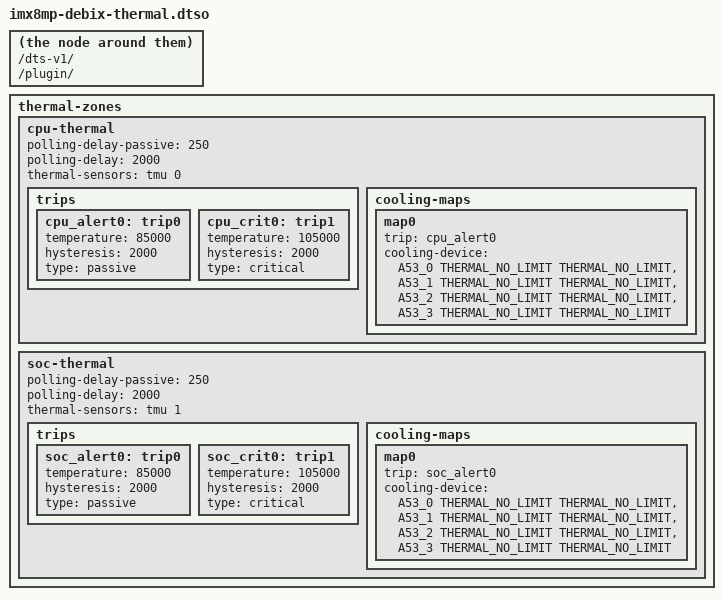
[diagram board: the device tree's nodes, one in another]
/dts-v1/;
/plugin/;

#include "imx8mp-pinfunc.h"
#include <dt-bindings/interrupt-controller/arm-gic.h>
#include <dt-bindings/thermal/thermal.h>

	thermal-zones {
		cpu-thermal {
			polling-delay-passive = <250>;
			polling-delay = <2000>;
			thermal-sensors = <&tmu 0>;
			trips {
				cpu_alert0: trip0 {
					temperature = <85000>;
					hysteresis = <2000>;
					type = "passive";
				};

				cpu_crit0: trip1 {
					temperature = <105000>;
					hysteresis = <2000>;
					type = "critical";
				};
			};

			cooling-maps {
				map0 {
					trip = <&cpu_alert0>;
					cooling-device =
						<&A53_0 THERMAL_NO_LIMIT THERMAL_NO_LIMIT>,
						<&A53_1 THERMAL_NO_LIMIT THERMAL_NO_LIMIT>,
						<&A53_2 THERMAL_NO_LIMIT THERMAL_NO_LIMIT>,
						<&A53_3 THERMAL_NO_LIMIT THERMAL_NO_LIMIT>;
				};
			};
		};

		soc-thermal {
			polling-delay-passive = <250>;
			polling-delay = <2000>;
			thermal-sensors = <&tmu 1>;
			trips {
				soc_alert0: trip0 {
					temperature = <85000>;
					hysteresis = <2000>;
					type = "passive";
				};

				soc_crit0: trip1 {
					temperature = <105000>;
					hysteresis = <2000>;
					type = "critical";
				};
			};

			cooling-maps {
				map0 {
					trip = <&soc_alert0>;
					cooling-device =
						<&A53_0 THERMAL_NO_LIMIT THERMAL_NO_LIMIT>,
						<&A53_1 THERMAL_NO_LIMIT THERMAL_NO_LIMIT>,
						<&A53_2 THERMAL_NO_LIMIT THERMAL_NO_LIMIT>,
						<&A53_3 THERMAL_NO_LIMIT THERMAL_NO_LIMIT>;
				};
			};
		};
	};

